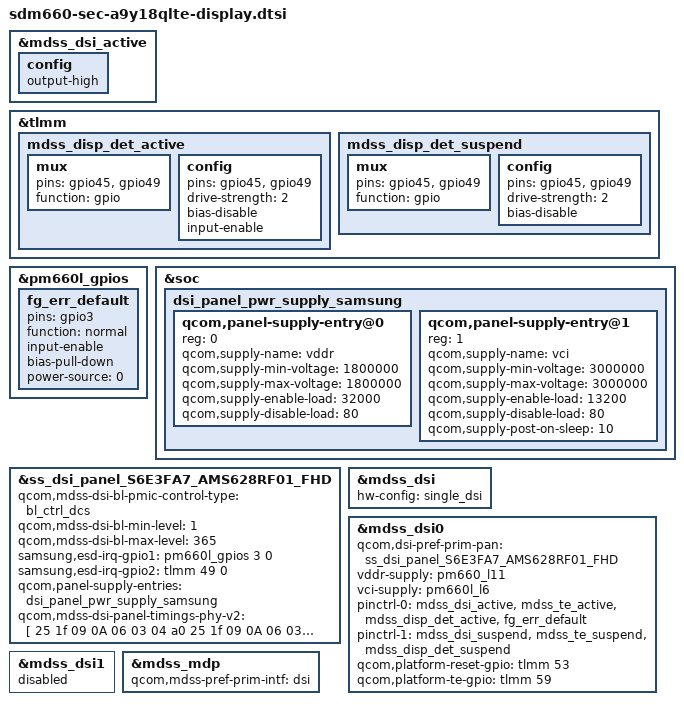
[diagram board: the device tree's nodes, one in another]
// SPDX-License-Identifier: GPL-2.0-only
/*
 * a9y18qlte display: S6E3FA7 AMS628RF01 FHD+ AMOLED, command mode,
 * from sdm660-sec-a9y18qlte-display-r01.dtsi on 4.4.
 */

#include "../../../../../../../drivers/video/fbdev/msm/samsung/S6E3FA7_AMS628RF01/dsi_panel_S6E3FA7_AMS628RF01_fhd_octa_cmd.dtsi"
#include "../../../../../../../drivers/video/fbdev/msm/samsung/PBA_BOOTING/dsi_panel_PBA_BOOTING_fhd_video.dtsi"

/* Reset (gpio53) and TE (gpio59) use the qcom groups; Samsung keeps reset high */
&mdss_dsi_active {
	config {
		output-high;
	};
};

&tlmm {
	/* Panel error detect lines, used for ESD recovery */
	mdss_disp_det_active: mdss_disp_det_active {
		mux {
			pins = "gpio45", "gpio49";
			function = "gpio";
		};
		config {
			pins = "gpio45", "gpio49";
			drive-strength = <2>;
			bias-disable;
			input-enable;
		};
	};

	mdss_disp_det_suspend: mdss_disp_det_suspend {
		mux {
			pins = "gpio45", "gpio49";
			function = "gpio";
		};
		config {
			pins = "gpio45", "gpio49";
			drive-strength = <2>;
			bias-disable;
		};
	};
};

&pm660l_gpios {
	/* GPIO 3, FG_ERR from the panel */
	fg_err_default: fg_err_default {
		pins = "gpio3";
		function = "normal";
		input-enable;
		bias-pull-down;
		power-source = <0>;
	};
};

&soc {
	dsi_panel_pwr_supply_samsung: dsi_panel_pwr_supply_samsung {
		#address-cells = <1>;
		#size-cells = <0>;

		qcom,panel-supply-entry@0 {
			reg = <0>;
			qcom,supply-name = "vddr";
			qcom,supply-min-voltage = <1800000>;
			qcom,supply-max-voltage = <1800000>;
			qcom,supply-enable-load = <32000>;
			qcom,supply-disable-load = <80>;
		};

		qcom,panel-supply-entry@1 {
			reg = <1>;
			qcom,supply-name = "vci";
			qcom,supply-min-voltage = <3000000>;
			qcom,supply-max-voltage = <3000000>;
			qcom,supply-enable-load = <13200>;
			qcom,supply-disable-load = <80>;
			qcom,supply-post-on-sleep = <10>;
		};
	};
};

&ss_dsi_panel_S6E3FA7_AMS628RF01_FHD {
	qcom,mdss-dsi-bl-pmic-control-type = "bl_ctrl_dcs";
	qcom,mdss-dsi-bl-min-level = <1>;
	qcom,mdss-dsi-bl-max-level = <365>;

	samsung,esd-irq-gpio1 = <&pm660l_gpios 3 0>;	/* FG_ERR */
	samsung,esd-irq-gpio2 = <&tlmm 49 0>;		/* EL_ON1_DET */

	qcom,panel-supply-entries = <&dsi_panel_pwr_supply_samsung>;

	qcom,mdss-dsi-panel-timings-phy-v2 = [
		25 1f 09 0A 06 03 04 a0
		25 1f 09 0A 06 03 04 a0
		25 1f 09 0A 06 03 04 a0
		25 1f 09 0A 06 03 04 a0
		25 1f 08 0A 06 03 04 a0
	];
};

&mdss_dsi {
	hw-config = "single_dsi";
};

&mdss_dsi0 {
	qcom,dsi-pref-prim-pan = <&ss_dsi_panel_S6E3FA7_AMS628RF01_FHD>;
	vddr-supply = <&pm660_l11>;
	vci-supply = <&pm660l_l6>;

	pinctrl-names = "mdss_default", "mdss_sleep";
	pinctrl-0 = <&mdss_dsi_active &mdss_te_active &mdss_disp_det_active
		     &fg_err_default>;
	pinctrl-1 = <&mdss_dsi_suspend &mdss_te_suspend &mdss_disp_det_suspend>;

	qcom,platform-reset-gpio = <&tlmm 53 0>;
	qcom,platform-te-gpio = <&tlmm 59 0>;
};

&mdss_dsi1 {
	status = "disabled";
};

&mdss_mdp {
	qcom,mdss-pref-prim-intf = "dsi";
};
